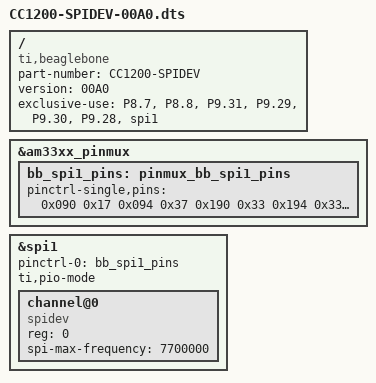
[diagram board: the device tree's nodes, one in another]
/*
* Copyright (C) 2015 Anh Luong <luong@eng.utah.edu>
*
* This program is free software; you can redistribute it and/or modify
* it under the terms of the GNU General Public License version 2 as
* published by the Free Software Foundation.
*/
/dts-v1/;
/plugin/;

/ {
	compatible = "ti,beaglebone", "ti,beaglebone-black", "ti,beaglebone-green";

	/* identification */
	part-number = "CC1200-SPIDEV";
	version = "00A0";

	/* state the resources this cape uses */
	exclusive-use =
		/* the pin header uses */
		"P8.7",		/* reset */
		"P8.8",		/* gpio0 */
		"P9.31",	/* spi1_sclk */
		"P9.29",	/* spi1_d0 */
		"P9.30",	/* spi1_d1 */
		"P9.28",	/* spi1_cs0 */
		/* the hardware ip uses */
		"spi1";

	fragment@0 {
		target = <&am33xx_pinmux>;
		__overlay__ {
			/* default state has all gpios released and mode set to uart1 */
			bb_spi1_pins: pinmux_bb_spi1_pins {
				pinctrl-single,pins = <
					0x090 0x17  /* P8.7  CC1200_RESET  O_PULLUP | MODE7-GPIO2[2] */
          			0x094 0x37  /* P8.8  CC1200_IRQ    I_PULLUP | MODE7-GPIO2[3] */
					0x190 0x33	/* mcasp0_aclkx.spi1_sclk, OUTPUT_PULLUP | MODE3 */
					0x194 0x33	/* mcasp0_fsx.spi1_d0, INPUT_PULLUP | MODE3 */
					0x198 0x13	/* mcasp0_axr0.spi1_d1, OUTPUT_PULLUP | MODE3 */
					0x19c 0x13	/* mcasp0_ahclkr.spi1_cs0, OUTPUT_PULLUP | MODE3 */
				>;
			};
		};
	};

	fragment@1 {
		target = <&spi1>;
		__overlay__ {
			#address-cells = <1>;
			#size-cells = <0>;

			status = "okay";
			pinctrl-names = "default";
			pinctrl-0 = <&bb_spi1_pins>;
			ti,pio-mode; /* disable dma when used as an overlay, dma gets stuck at 160 bits */
			
			channel@0 {
				#address-cells = <1>;
				#size-cells = <0>;

				compatible = "spidev";

				reg = <0>;
				spi-max-frequency = <7700000>;
			};
		};
	};
};
